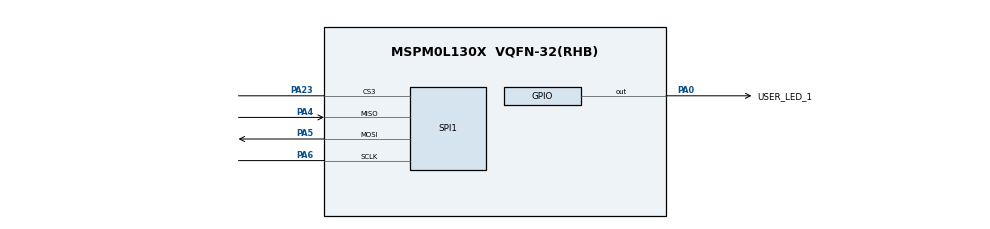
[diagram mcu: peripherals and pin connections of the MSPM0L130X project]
/**
 * @cliArgs --device "MSPM0L130X" --package "VQFN-32(RHB)" --part "Default" --product "mspm0_sdk@2.01.00.03"
 * @versions {"tool":"1.19.0+3426"}
 */

/**
 * Import the modules used in this configuration.
 */
const GPIO   = scripting.addModule("/ti/driverlib/GPIO", {}, false);
const GPIO1  = GPIO.addInstance();
const SPI    = scripting.addModule("/ti/driverlib/SPI", {}, false);
const SPI1   = SPI.addInstance();
const SYSCTL = scripting.addModule("/ti/driverlib/SYSCTL");

/**
 * Write custom configuration values to the imported modules.
 */
GPIO1.$name                          = "GPIO_LEDS";
GPIO1.associatedPins[0].$name        = "USER_LED_1";
GPIO1.associatedPins[0].initialValue = "SET";
GPIO1.associatedPins[0].pin.$assign  = "PA0";

const Board = scripting.addModule("/ti/driverlib/Board", {}, false);

SPI1.$name                      = "SPI_0";
SPI1.phase                      = "1";
SPI1.targetBitRate              = 4000000;
SPI1.chipSelect                 = ["3"];
SPI1.peripheral.sclkPin.$assign = "PA6";
SPI1.peripheral.mosiPin.$assign = "PA5";
SPI1.peripheral.misoPin.$assign = "PA4";
SPI1.peripheral.cs3Pin.$assign  = "PA23";
SPI1.sclkPinConfig.$name        = "ti_driverlib_gpio_GPIOPinGeneric0";
SPI1.mosiPinConfig.$name        = "ti_driverlib_gpio_GPIOPinGeneric1";
SPI1.misoPinConfig.$name        = "ti_driverlib_gpio_GPIOPinGeneric2";
SPI1.cs3PinConfig.$name         = "ti_driverlib_gpio_GPIOPinGeneric3";

SYSCTL.clockTreeEn = true;

/**
 * Pinmux solution for unlocked pins/peripherals. This ensures that minor changes to the automatic solver in a future
 * version of the tool will not impact the pinmux you originally saw.  These lines can be completely deleted in order to
 * re-solve from scratch.
 */
Board.peripheral.$suggestSolution          = "DEBUGSS";
Board.peripheral.swclkPin.$suggestSolution = "PA20";
Board.peripheral.swdioPin.$suggestSolution = "PA19";
SPI1.peripheral.$suggestSolution           = "SPI0";
